# ESP32-C6 register map
Vendor: ESPRESSIF SYSTEMS (SHANGHAI) CO., LTD.; Series: ESP32 C-Series; File version: 2
CPU: RV32IMC r0p0, little endian, no MPU, no FPU, 4 interrupt priority bits
Address unit: 32 bits
Registers are 32-bit, read-write, reset 0x0 unless marked. A register's access mark holds for its fields unless they carry their own. Offsets are from the block's base; [hi:lo] are bit positions; {n}, {i} and the like mark numbered series.

## MEM_MONITOR — Peripheral MEM_MONITOR
Base 0x60092000
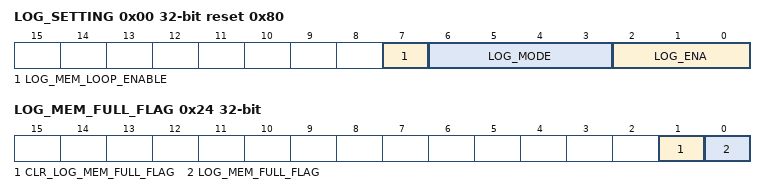
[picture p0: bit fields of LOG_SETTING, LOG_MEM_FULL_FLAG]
0x00 LOG_SETTING reset 0x80 — log config regsiter
  [7] LOG_MEM_LOOP_ENABLE — Set 1 enable mem_loop, it will loop write at the range of MEM_START and MEM_END
  [6:3] LOG_MODE — This field must be onehot. 4'b0001 : WR monitor, 4'b0010: WORD monitor, 4'b0100: HALFWORD monitor, 4'b1000: BYTE monitor.
  [2:0] LOG_ENA — enable bus log. BIT0: hp-cpu, BIT1: lp-cpu, BIT2: DMA.
0x04 LOG_CHECK_DATA — check data regsiter
  [31:0] LOG_CHECK_DATA — The special check data, when write this special data, it will trigger logging.
0x08 LOG_DATA_MASK — check data mask register
  [3:0] LOG_DATA_MASK — byte mask enable, BIT0 mask the first byte of MEM_MONITOR_LOG_CHECK_DATA, and BIT1 mask second byte, and so on.
0x0C LOG_MIN — log boundary regsiter
  [31:0] LOG_MIN — the min address of log range
0x10 LOG_MAX — log boundary regsiter
  [31:0] LOG_MAX — the max address of log range
0x14 LOG_MEM_START — log message store range register
  [31:0] LOG_MEM_START — the start address of writing logging message
0x18 LOG_MEM_END — log message store range register
  [31:0] LOG_MEM_END — the end address of writing logging message
0x1C LOG_MEM_CURRENT_ADDR ro — current writing address.
  [31:0] LOG_MEM_CURRENT_ADDR — means next writing address
0x20 LOG_MEM_ADDR_UPDATE wo — writing address update
  [0] LOG_MEM_ADDR_UPDATE — Set 1 to updata MEM_MONITOR_LOG_MEM_CURRENT_ADDR, when set 1, MEM_MONITOR_LOG_MEM_CURRENT_ADDR will update to MEM_MONITOR_LOG_MEM_START
0x24 LOG_MEM_FULL_FLAG access per field — full flag status register
  [1] CLR_LOG_MEM_FULL_FLAG wo — Set 1 to clr MEM_MONITOR_LOG_MEM_FULL_FLAG
  [0] LOG_MEM_FULL_FLAG ro — 1 means memory write loop at least one time at the range of MEM_START and MEM_END
0x28 CLOCK_GATE — clock gate force on register
  [0] CLK_EN — Set 1 to force on the clk of mem_monitor register
0x3FC DATE reset 0x2202140 — version register
  [27:0] DATE

## OTP_DEBUG — Peripheral OTP_DEBUG
Base 0x600B3C00
0x00 WR_DIS ro — Otp debuger block0 data register1.
  [31:0] BLOCK0_WR_DIS — Otp block0 write disable data.
{0x0+4i} BLK0_BACKUP1_W{i} ro (i=1..5) — Otp debuger block0 data register{i+1}.
  [31:0] OTP_BEBUG_BLOCK0_BACKUP1_W{i} — Otp block0 backup1 word{i} data.
{0x14+4i} BLK0_BACKUP2_W{i} ro (i=1..5) — Otp debuger block0 data register{i+6}.
  [31:0] OTP_BEBUG_BLOCK0_BACKUP2_W{i} — Otp block0 backup2 word{i} data.
{0x28+4i} BLK0_BACKUP3_W{i} ro (i=1..5) — Otp debuger block0 data register{i+11}.
  [31:0] OTP_BEBUG_BLOCK0_BACKUP3_W{i} — Otp block0 backup3 word{i} data.
{0x3C+4i} BLK0_BACKUP4_W{i} ro (i=1..5) — Otp debuger block0 data register{i+16}.
  [31:0] OTP_BEBUG_BLOCK0_BACKUP4_W{i} — Otp block0 backup4 word{i} data.
{0x50+4i} BLK1_W{i} ro (i=1..9) — Otp debuger block1 data register{i}.
  [31:0] BLOCK1_W{i} — Otp block1 word{i} data.
{0x74+4i} BLK2_W{i} ro (i=1..11) — Otp debuger block2 data register{i}.
  [31:0] BLOCK2_W{i} — Otp block2 word{i} data.
{0xA0+4i} BLK3_W{i} ro (i=1..11) — Otp debuger block3 data register{i}.
  [31:0] BLOCK3_W{i} — Otp block3 word{i} data.
{0xCC+4i} BLK4_W{i} ro (i=1..9) — Otp debuger block4 data register{i}.
  [31:0] BLOCK4_W{i} — Otp block4 word{i} data.
0xF4 BLK4_W10 ro — Otp debuger block4 data registe10.
  [31:0] BLOCK4_W10 — Otp block4 word10 data.
0xF8 BLK4_W11 ro — Otp debuger block4 data register11.
  [31:0] BLOCK4_W11 — Otp block4 word11 data.
{0xF8+4i} BLK5_W{i} ro (i=1..11) — Otp debuger block5 data register{i}.
  [31:0] BLOCK5_W{i} — Otp block5 word{i} data.
{0x124+4i} BLK6_W{i} ro (i=1..11) — Otp debuger block6 data register{i}.
  [31:0] BLOCK6_W{i} — Otp block6 word{i} data.
{0x150+4i} BLK7_W{i} ro (i=1..11) — Otp debuger block7 data register{i}.
  [31:0] BLOCK7_W{i} — Otp block7 word{i} data.
{0x17C+4i} BLK8_W{i} ro (i=1..11) — Otp debuger block8 data register{i}.
  [31:0] BLOCK8_W{i} — Otp block8 word{i} data.
{0x1A8+4i} BLK9_W{i} ro (i=1..11) — Otp debuger block9 data register{i}.
  [31:0] BLOCK9_W{i} — Otp block9 word{i} data.
{0x1D4+4i} BLK10_W{i} ro (i=1..9) — Otp debuger block10 data register{i}.
  [31:0] BLOCK10_W{i} — Otp block10 word{i} data.
0x1FC BLK10_W10 ro — Otp debuger block10 data register10.
  [31:0] BLOCK19_W10 — Otp block10 word10 data.
0x200 BLK10_W11 ro — Otp debuger block10 data register11.
  [31:0] BLOCK10_W11 — Otp block10 word11 data.
0x204 CLK — Otp debuger clk_en configuration register.
  [0] EN — Force clock on for this register file.
0x208 APB2OTP_EN — Otp_debuger apb2otp enable configuration register.
  [0] APB2OTP_EN — Debug mode enable signal.
0x20C DATE reset 0x20211028 — eFuse version register.
  [27:0] DATE — Stores otp_debug version.
